# LPC55S66_cm33_core1 register map
Vendor: nxp.com; File version: 1.0
CPU: CM33 r2p0, little endian, no MPU, no FPU, VTOR, 3 interrupt priority bits
Registers are 32-bit, read-write, reset 0x0 unless marked. A register's access mark holds for its fields unless they carry their own. Offsets are from the block's base; [hi:lo] are bit positions; {n}, {i} and the like mark numbered series.

## FLASH_CFPA0 — FLASH_CFPA
Base 0x0009E000
Same registers: FLASH_CFPA_SCRATCH 0x0009DE00, FLASH_CFPA1 0x0009E200
0x00 HEADER
  [31:0] FIELD
0x04 VERSION
  [31:0] FIELD
0x08 S_FW_Version — Secure firmware version (Monotonic counter)
  [31:0] FIELD
0x0C NS_FW_Version — Non-Secure firmware version (Monotonic counter)
  [31:0] FIELD
0x10 IMAGE_KEY_REVOKE — Image key revocation ID (Monotonic counter)
  [31:0] FIELD
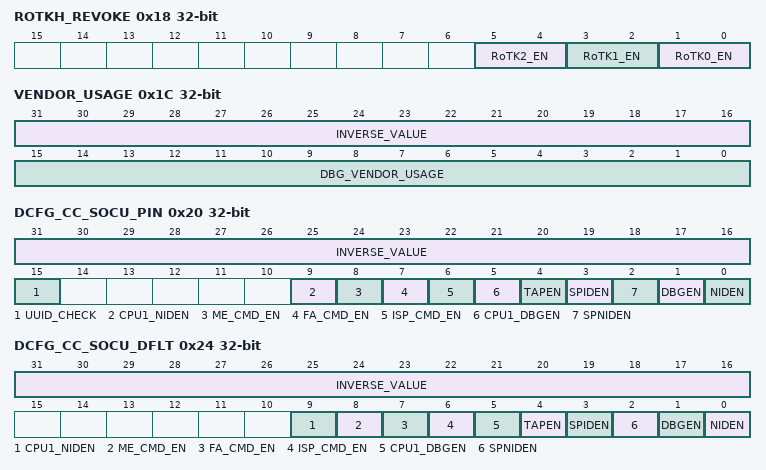
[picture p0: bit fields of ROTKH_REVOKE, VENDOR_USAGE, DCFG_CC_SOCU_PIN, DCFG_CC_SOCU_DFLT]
0x18 ROTKH_REVOKE
  [5:4] RoTK2_EN — RoT Key 2 enable. 00 - Invalid 01 - Enabled 10, 11 - Key revoked
  [3:2] RoTK1_EN — RoT Key 1 enable. 00 - Invalid 01 - Enabled 10, 11 - Key revoked
  [1:0] RoTK0_EN — RoT Key 0 enable. 00 - Invalid 01 - Enabled 10, 11 - Key revoked
0x1C VENDOR_USAGE
  [31:16] INVERSE_VALUE — inverse value of bits [15:0]
  [15:0] DBG_VENDOR_USAGE
0x20 DCFG_CC_SOCU_PIN — With TZ-M, the part can be sold by level 1 customers (secure code developer) to level-2 customers who develops non-secure code only. - In this scenario, or easy of development, Level-I customer releases the part to always allow non-secure debug. - To allow level-2 customers to further seal the part DCFG_CC_SOCU_NS is used. - ROM will use this word to further restrict the debug access.
  [31:16] INVERSE_VALUE — inverse value of bits [15:0]
  [15] UUID_CHECK — Enforce UUID match during Debug authentication.
  [9] CPU1_NIDEN — CPU1 (Micro cortex M33) non-invasive debug enable
    0=Use DAP to enable; 1=Fixed state
  [8] ME_CMD_EN — Flash Mass Erase Command enable
    0=Use DAP to enable; 1=Fixed state
  [7] FA_CMD_EN — FA Command enable
    0=Use DAP to enable; 1=Fixed state
  [6] ISP_CMD_EN — ISP Boot Command enable
    0=Use DAP to enable; 1=Fixed state
  [5] CPU1_DBGEN — CPU1 (Micro cortex M33) invasive debug enable
    0=Use DAP to enable; 1=Fixed state
  [4] TAPEN — JTAG TAP enable
    0=Use DAP to enable; 1=Fixed state
  [3] SPIDEN — Secure invasive debug enable
    0=Use DAP to enable; 1=Fixed state
  [2] SPNIDEN — Secure non-invasive debug enable
    0=Use DAP to enable; 1=Fixed state
  [1] DBGEN — Non Secure debug enable
    0=Use DAP to enable; 1=Fixed state
  [0] NIDEN — Non Secure non-invasive debug enable
    0=Use DAP to enable; 1=Fixed state
0x24 DCFG_CC_SOCU_DFLT — With TZ-M, the part can be sold by level 1 customers (secure code developer) to level-2 customers who develops non-secure code only. - In this scenario, or easy of development, Level-I customer releases the part to always allow non-secure debug. - To allow level-2 customers to further seal the part DCFG_CC_SOCU_NS is used. - ROM will use this word to further restrict the debug access.
  [31:16] INVERSE_VALUE — inverse value of bits [15:0]
  [9] CPU1_NIDEN — CPU1 (Micro cortex M33) non-invasive debug fixed state
    0=DISABLE; 1=ENABLE
  [8] ME_CMD_EN — Flash Mass Erase Command fixed state
    0=DISABLE; 1=ENABLE
  [7] FA_CMD_EN — FA Command fixed state
    0=DISABLE; 1=ENABLE
  [6] ISP_CMD_EN — ISP Boot Command fixed state
    0=DISABLE; 1=ENABLE
  [5] CPU1_DBGEN — CPU1 (Micro cortex M33) invasive debug fixed state
    0=DISABLE; 1=ENABLE
  [4] TAPEN — JTAG TAP fixed state
    0=DISABLE; 1=ENABLE
  [3] SPIDEN — Secure invasive debug fixed state
    0=DISABLE; 1=ENABLE
  [2] SPNIDEN — Secure non-invasive debug fixed state
    0=DISABLE; 1=ENABLE
  [1] DBGEN — Non Secure debug fixed state
    0=DISABLE; 1=ENABLE
  [0] NIDEN — Non Secure non-invasive debug fixed state
    0=DISABLE; 1=ENABLE
0x28 ENABLE_FA_MODE — Enable FA mode. SET_FA_MODE Command should write 0xC33CA55A to this word to indicate boot ROM to enter FA mode.
  [31:0] FIELD
0x2C CMPA_PROG_IN_PROGRESS — CMPA Page programming on going. This field shall be set to 0x5CC55AA5 in the active CFPA page each time CMPA page programming is going on. It shall always be set to 0x00000000 in the CFPA scratch area.
  [31:0] FIELD
{0x30+4i} PRINCE_REGION0_IV_CODE{i} (PRINCE_REGION0_IV_CODE view) (i=0..13)
  [31:0] FIELD
{0x30+0x38*i} PRINCE_REGION{i}_IV_HEADER0 (PRINCE_REGION{i}_IV_CODE view) (i=0..2)
  [31:0] FIELD
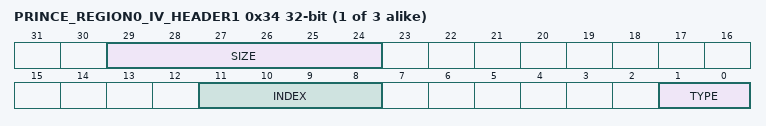
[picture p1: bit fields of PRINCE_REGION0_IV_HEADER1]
{0x34+0x38*i} PRINCE_REGION{i}_IV_HEADER1 (PRINCE_REGION{i}_IV_CODE view) (i=0..2)
  [29:24] SIZE, [11:8] INDEX, [1:0] TYPE
{0x38+4i} PRINCE_REGION0_IV_BODY{i} (PRINCE_REGION0_IV_CODE view) (i=0..11)
  [31:0] FIELD
{0x68+4i} PRINCE_REGION1_IV_CODE{i} (PRINCE_REGION1_IV_CODE view) (i=0..13)
  [31:0] FIELD
{0x70+4i} PRINCE_REGION1_IV_BODY{i} (PRINCE_REGION1_IV_CODE view) (i=0..11)
  [31:0] FIELD
{0xA0+4i} PRINCE_REGION2_IV_CODE{i} (PRINCE_REGION2_IV_CODE view) (i=0..13)
  [31:0] FIELD
{0xA8+4i} PRINCE_REGION2_IV_BODY{i} (PRINCE_REGION2_IV_CODE view) (i=0..11)
  [31:0] FIELD
{0x100+4i} CUSTOMER_DEFINED[{i}] (i=0..55) — Customer Defined (Programable through ROM API)
  [31:0] FIELD
{0x1E0+4i} SHA256_DIGEST[{i}] (i=0..7) — SHA256_DIGEST0 for DIGEST[31:0] SHA256_DIGEST1 for DIGEST[63:32] SHA256_DIGEST2 for DIGEST[95:64] SHA256_DIGEST3 for DIGEST[127:96] SHA256_DIGEST4 for DIGEST[159:128] SHA256_DIGEST5 for DIGEST[191:160] SHA256_DIGEST6 for DIGEST[223:192] SHA256_DIGEST7 for DIGEST[255:224]
  [31:0] FIELD

## Notices in the file
Copyright 2016-2019 NXP
All rights reserved.
SPDX-License-Identifier: BSD-3-Clause
